# STM32H7P4xx register map
File version: 1.0
Registers are 32-bit, read-write, reset 0x0 unless marked. A register's access mark holds for its fields unless they carry their own. Offsets are from the block's base; [hi:lo] are bit positions; lines under a group give offsets from that group; {n}, {i} and the like mark numbered series; 'fields as' and 'values as' point back to an identical list.

## FLASH — FLASH Registers
Base 0x52002000
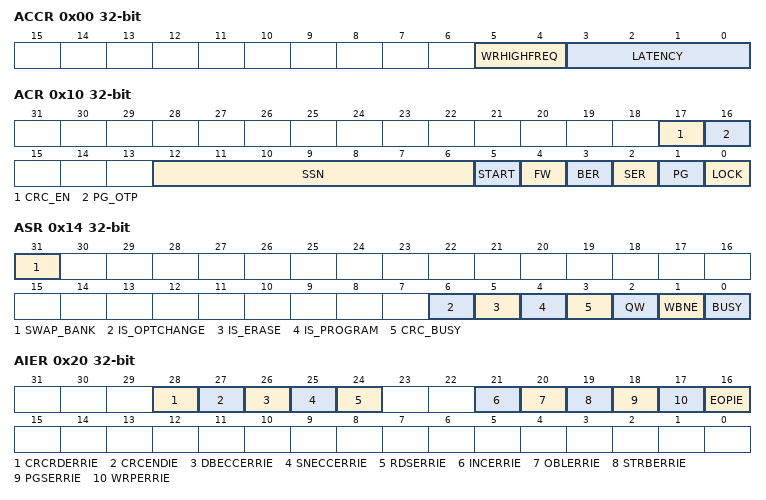
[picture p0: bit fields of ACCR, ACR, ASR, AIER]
0x00 ACCR — FLASH access control register
  [5:4] WRHIGHFREQ — WRHIGHFREQ[1:0] bits (Flash signal delay)
  [3:0] LATENCY — LATENCY[3:0] bits (Read latency)
0x04 AKEYR — FLASH bank A control key register
  [31:0] CUKEY — Control unlock key
0x10 ACR — FLASH bank A control register
  [17] CRC_EN — CRC enable
  [16] PG_OTP — Program Enable for OTP Area
  [12:6] SSN — Sector erase selection number
  [5] START — Erase start control bit
  [4] FW — Force write
  [3] BER — Bank erase request
  [2] SER — Sector erase request
  [1] PG — Internal buffer control bit
  [0] LOCK — Configuration lock bit
0x14 ASR ro — FLASH bank A status register
  [31] SWAP_BANK — SWAP_BANK (Swapped bank)
  [6] IS_OPTCHANGE — Is an option change
  [5] IS_ERASE — Is an erase
  [4] IS_PROGRAM
  [3] CRC_BUSY — CRC busy flag
  [2] QW — Wait queue flag
  [1] WBNE — Write buffer not empty flag
  [0] BUSY — Busy flag
0x20 AIER — FLASH bank A interrupt enable register
  [28] CRCRDERRIE — CRC read error interrupt enable bit
  [27] CRCENDIE — CRC end of calculation interrupt enable bit
  [26] DBECCERRIE — ECC double detection error interrupt enable bit
  [25] SNECCERRIE — ECC single correction error interrupt enable bit
  [24] RDSERRIE — Read security error interrupt enable bit
  [21] INCERRIE — Inconsistency error interrupt enable bit
  [20] OBLERRIE — Option byte loading error interrupt enable bit
  [19] STRBERRIE — Strobe error interrupt enable bit
  [18] PGSERRIE — Programming sequence error interrupt enable bit
  [17] WRPERRIE — Write protection error interrupt enable bit
  [16] EOPIE — End of program interrupt enable bit
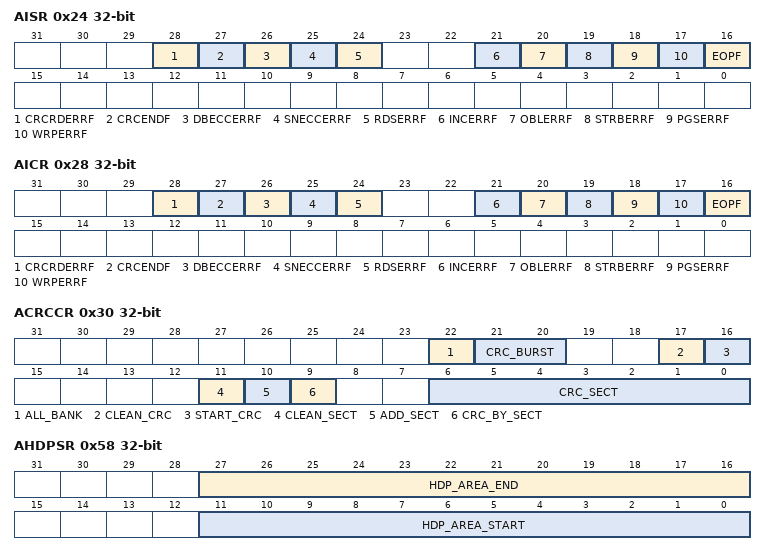
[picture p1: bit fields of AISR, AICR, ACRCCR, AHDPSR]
0x24 AISR ro — FLASH bank A interrupt status register
  [28] CRCRDERRF — CRC read error flag
  [27] CRCENDF — CRC end of calculation flag
  [26] DBECCERRF — ECC double error flag
  [25] SNECCERRF — ECC single error flag
  [24] RDSERRF — Read security error flag
  [21] INCERRF — Inconsistency error flag
  [20] OBLERRF — Option byte loading error flag
  [19] STRBERRF — Strobe error flag
  [18] PGSERRF — Programming sequence error flag
  [17] WRPERRF — Write protection error flag
  [16] EOPF — End of program flag
0x28 AICR — FLASH bank A interrupt clear register
  [28] CRCRDERRF — CRC read error flag clear
  [27] CRCENDF — CRC end flag clear
  [26] DBECCERRF — ECC double error flag clear
  [25] SNECCERRF — ECC single error flag clear
  [24] RDSERRF — Read security error flag clear
  [21] INCERRF — Inconsistency error flag clear
  [20] OBLERRF — Option byte loading error flag clear
  [19] STRBERRF — Strobe error flag clear
  [18] PGSERRF — Programming sequence error flag clear
  [17] WRPERRF — Write protection error flag clear
  [16] EOPF — End of program flag clear
0x30 ACRCCR — FLASH bank A CRC control register
  [22] ALL_BANK — ALL_BANK (All sectors in bank selection)
  [21:20] CRC_BURST — CRC_BURST[1:0] bits (CRC burst size)
  [17] CLEAN_CRC — CLEAN_CRC (CRC clear bit)
  [16] START_CRC — START_CRC (CRC start bit)
  [11] CLEAN_SECT — CLEAN_SECT (CRC sector list clear bit)
  [10] ADD_SECT — ADD_SECT (CRC sector select bit)
  [9] CRC_BY_SECT — CRC_BY_SECT (CRC sector mode select bit)
  [6:0] CRC_SECT — CRC_SECT[6:0] bits (CRC sector number)
0x34 ACRCSADDR — FLASH bank A CRC start address register
  [19:2] CRC_START_ADDR — CRC start address
0x38 ACRCEADDR — FLASH bank A CRC end address register
  [19:2] CRC_END_ADDR — CRC end address
0x3C CRCDATAR ro — FLASH CRC data register
  [31:0] CRC_DATA — CRC result
0x40 AECCSFADDR ro — FLASH bank A ECC single error fail address
  [31:0] SEC_FADD — ECC single error correction fail address
0x44 AECCDFADDR ro — FLASH bank A ECC double error fail address
  [31:0] DED_FADD — ECC double error detection fail address
0x50 AWRPSR ro — FLASH bank A write protection status register
  [31:0] WRPSG — WRPSG[31:0] bits (Write protection for sector group n in bank x (n=0 to 127))
0x54 AWRPSRP — FLASH bank A write protection status register programming
  [31:0] WRPSG — WRPSG[31:0] bits (Write protection for sector group n in bank x programming (n=0 to 127))
0x58 AHDPSR ro — FLASH bank A hide protection status register
  [27:16] HDP_AREA_END — HDP_AREA_END[11:0] bits (Hide protection user flash area end for bank x)
  [11:0] HDP_AREA_START — HDP_AREA_START[11:0] bits (Hide protection user flash area start for bank x)
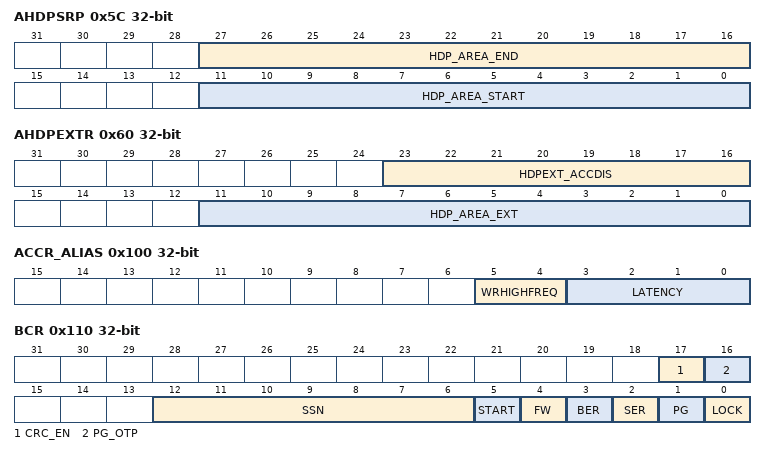
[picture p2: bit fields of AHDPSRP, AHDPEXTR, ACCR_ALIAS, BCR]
0x5C AHDPSRP — FLASH bank A hide protection status register programming
  [27:16] HDP_AREA_END — HDP_AREA_END[11:0] bits (Hide protection user flash area end programming for bank x)
  [11:0] HDP_AREA_START — HDP_AREA_START[11:0] bits (Hide protection user flash area start programming for bank x)
0x60 AHDPEXTR — FLASH bank A HDP extension register
  [23:16] HDPEXT_ACCDIS — HDPEXT_ACCDIS[7:0] bits (HDP extension area access disable for bank x)
  [11:0] HDP_AREA_EXT — HDP_AREA_EXT[11:0] bits (HDP extension area end for bank x)
0x100 ACCR_ALIAS — FLASH access control register
  [5:4] WRHIGHFREQ — Flash signal delay
  [3:0] LATENCY — Read latency
0x104 BKEYR — FLASH bank B control key register
  [31:0] CUKEY — CUKEY[31:0] bits (Control unlock key)
0x110 BCR — FLASH bank B control register
  [17] CRC_EN — CRC_EN (CRC enable)
  [16] PG_OTP — PG_OTP (Program Enable for OTP Area)
  [12:6] SSN — SSN[6:0] bits (Sector erase selection number)
  [5] START — START (Erase start control bit)
  [4] FW — FW (Force write)
  [3] BER — BER (Bank erase request)
  [2] SER — SER (Sector erase request)
  [1] PG — PG (Internal buffer control bit)
  [0] LOCK — LOCK (Configuration lock bit)
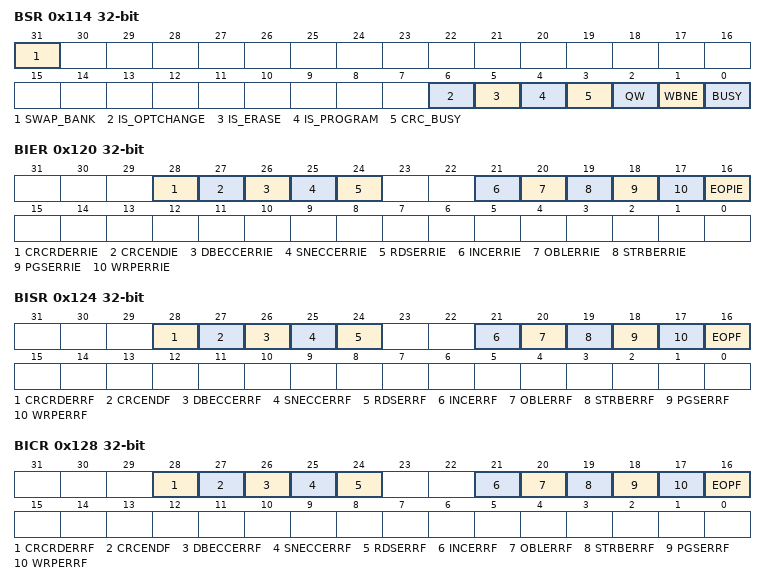
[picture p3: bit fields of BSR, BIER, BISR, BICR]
0x114 BSR ro — FLASH bank B status register
  [31] SWAP_BANK — SWAP_BANK (Swapped bank)
  [6] IS_OPTCHANGE — IS_OPTCHANGE (Is an option change)
  [5] IS_ERASE — IS_ERASE (Is an erase)
  [4] IS_PROGRAM — IS_PROGRAM (Is a program)
  [3] CRC_BUSY — CRC_BUSY (CRC busy flag)
  [2] QW — QW (Wait queue flag)
  [1] WBNE — WBNE (Write buffer not empty flag)
  [0] BUSY — BUSY (Busy flag)
0x120 BIER — FLASH bank B interrupt enable register
  [28] CRCRDERRIE — CRCRDERRIE (CRC read error interrupt enable bit)
  [27] CRCENDIE — CRCENDIE (CRC end of calculation interrupt enable bit)
  [26] DBECCERRIE — DBECCERRIE (ECC double detection error interrupt enable bit)
  [25] SNECCERRIE — SNECCERRIE (ECC single correction error interrupt enable bit)
  [24] RDSERRIE — RDSERRIE (Read security error interrupt enable bit)
  [21] INCERRIE — INCERRIE (Inconsistency error interrupt enable bit)
  [20] OBLERRIE — OBLERRIE (Option byte loading error interrupt enable bit)
  [19] STRBERRIE — STRBERRIE (Strobe error interrupt enable bit)
  [18] PGSERRIE — PGSERRIE (Programming sequence error interrupt enable bit)
  [17] WRPERRIE — WRPERRIE (Write protection error interrupt enable bit)
  [16] EOPIE — EOPIE (End-of-program interrupt control bit)
0x124 BISR ro — FLASH bank B interrupt status register
  [28] CRCRDERRF — CRCRDERRF (CRC read error flag)
  [27] CRCENDF — CRCENDF (CRC end flag)
  [26] DBECCERRF — DBECCERRF (ECC double error flag)
  [25] SNECCERRF — SNECCERRF (ECC single error flag)
  [24] RDSERRF — RDSERRF (Read security error flag)
  [21] INCERRF — INCERRF (Inconsistency error flag)
  [20] OBLERRF — OBLERRF (Option byte loading error flag)
  [19] STRBERRF — STRBERRF (Strobe error flag)
  [18] PGSERRF — PGSERRF (Programming sequence error flag)
  [17] WRPERRF — WRPERRF (Write protection error flag)
  [16] EOPF — EOPF (End-of-program flag)
0x128 BICR — FLASH bank B interrupt clear register
  [28] CRCRDERRF — CRCRDERRF (CRC error flag clear)
  [27] CRCENDF — CRCENDF (CRC end flag clear)
  [26] DBECCERRF — DBECCERRF (ECC double error flag clear)
  [25] SNECCERRF — SNECCERRF (ECC single error flag clear)
  [24] RDSERRF — RDSERRF (Read security error flag clear)
  [21] INCERRF — INCERRF (Inconsistency error flag clear)
  [20] OBLERRF — OBLERRF (Option byte loading error flag clear)
  [19] STRBERRF — STRBERRF (Strobe error flag clear)
  [18] PGSERRF — PGSERRF (Programming sequence error flag clear)
  [17] WRPERRF — WRPERRF (Write protection error flag clear)
  [16] EOPF — EOPF (End-of-program flag clear)
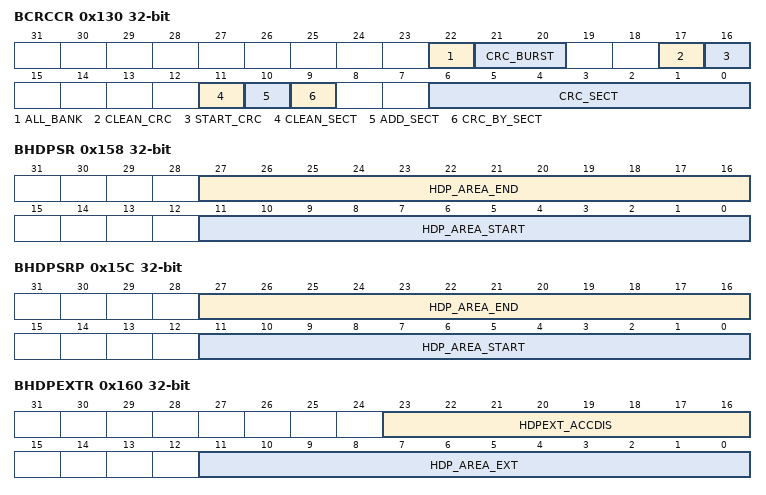
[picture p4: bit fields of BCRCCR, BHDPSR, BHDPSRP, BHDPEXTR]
0x130 BCRCCR — FLASH bank B CRC control register
  fields as ACRCCR
0x134 BCRCSADDR — FLASH bank B CRC start address register
  [19:2] CRC_START_ADDR — CRC_START_ADDR[17:0] bits (CRC start address)
0x138 BCRCEADDR — FLASH bank B CRC end address register
  [19:2] CRC_END_ADDR — CRC_END_ADDR[17:0] bits (CRC end address)
0x13C CRCDATAR_ALIAS ro — FLASH CRC data register
  [31:0] CRC_DATA — CRC result
0x140 BECCSFADDR ro — FLASH bank B ECC single error fail address
  [31:0] SEC_FADD — SEC_FADD[31:0] bits (ECC single error correction fail address)
0x144 BECCDFADDR ro — FLASH bank B ECC double error fail address
  [31:0] DED_FADD — DED_FADD[31:0] bits (ECC double error detection fail address)
0x150 BWRPSR ro — FLASH bank B write protection status register
  fields as AWRPSR
0x154 BWRPSRP — FLASH bank B write protection status register programming
  fields as AWRPSRP
0x158 BHDPSR ro — FLASH bank B hide protection status register
  fields as AHDPSR
0x15C BHDPSRP — FLASH bank B hide protection status register programming
  fields as AHDPSRP
0x160 BHDPEXTR — FLASH bank B HDP extension register
  fields as AHDPEXTR
0x200 OPTKEYR — FLASH options key register
  [31:0] OCUKEY — OCUKEY[31:0] bits (Options configuration unlock key)
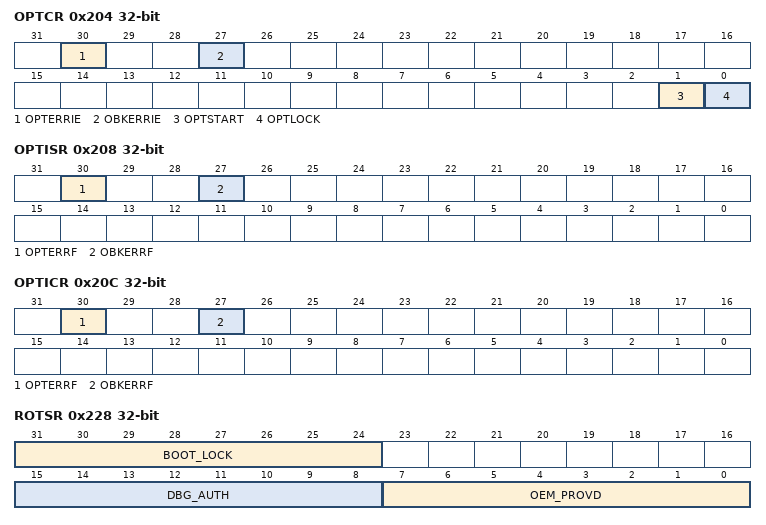
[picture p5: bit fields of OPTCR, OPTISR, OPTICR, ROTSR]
0x204 OPTCR — FLASH options control register
  [30] OPTERRIE — OPTERRIE (Option byte change error interrupt enable bit)
  [27] OBKERRIE — OBKERRIE (Option byte key error interrupt enable bit)
  [1] OPTSTART — OPTSTART (Options update start)
  [0] OPTLOCK — OPTLOCK (Options lock)
0x208 OPTISR ro — FLASH options interrupt status register
  [30] OPTERRF — OPTERRF (Option byte change error flag)
  [27] OBKERRF — OBKERRF (Option byte key error flag)
0x20C OPTICR — FLASH options interrupt clear register
  fields as OPTISR
0x210 OTPLSR ro — FLASH OTP lock status register
  [15:0] OTPL — OTPL[15:0] bits (OTP lock n (n=0 to 15))
0x214 OTPLSRP — FLASH OTP lock status register programming
  [15:0] OTPL — OTPL[15:0] bits (OTP lock n programming (n=0 to 15))
0x220 NVSR ro — FLASH non-volatile status register
  [7:0] NVSTATE — NVSTATE[7:0] bits (Non-volatile state)
0x224 NVSRP — FLASH security status register programming
  [7:0] NVSTATE — NVSTATE[7:0] bits (Non-volatile state programming)
0x228 ROTSR ro — FLASH RoT status register
  [31:24] BOOT_LOCK — BOOT_LOCK[7:0] bits (boot lock)
  [15:8] DBG_AUTH — DBG_AUTH[7:0] bits (Debug authentication method)
  [7:0] OEM_PROVD — OEM_PROVD[7:0] bits (OEM provisioned device)
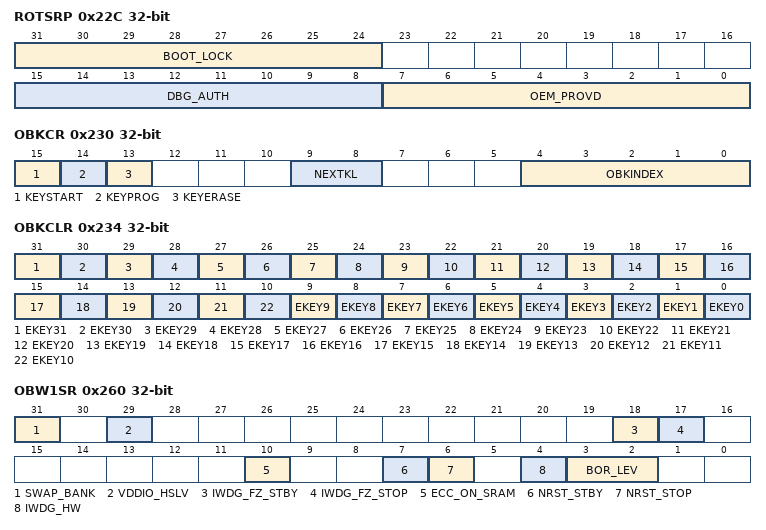
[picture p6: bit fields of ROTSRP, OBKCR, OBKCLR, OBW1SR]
0x22C ROTSRP — FLASH RoT status register programming
  [31:24] BOOT_LOCK — BOOT_LOCK[7:0] bits (Boot lock programming)
  [15:8] DBG_AUTH — DBG_AUTH[7:0] bits (Debug authentication method programming)
  [7:0] OEM_PROVD — OEM_PROVD[7:0] bits (OEM provisioned device)
0x230 OBKCR — FLASH option byte key control register
  [15] KEYSTART — KEYSTART (Key option start)
  [14] KEYPROG — KEYPROG (Key program)
  [13] KEYERASE — KEYERASE (Key erase)
  [9:8] NEXTKL — NEXTKL[1:0] bits (Next key level)
  [4:0] OBKINDEX — OBKINDEX[4:0] bits (Option byte key index)
0x234 OBKCLR — FLASH option byte key clear register
  [31] EKEY31 — EKEY31 (Erase key {i})
  [30] EKEY30 — EKEY30 (Erase key {i})
  [29] EKEY29 — EKEY29 (Erase key {i})
  [28] EKEY28 — EKEY28 (Erase key {i})
  [27] EKEY27 — EKEY27 (Erase key {i})
  [26] EKEY26 — EKEY26 (Erase key {i})
  [25] EKEY25 — EKEY25 (Erase key {i})
  [24] EKEY24 — EKEY24 (Erase key {i})
  [23] EKEY23 — EKEY23 (Erase key {i})
  [22] EKEY22 — EKEY22 (Erase key {i})
  [21] EKEY21 — EKEY21 (Erase key {i})
  [20] EKEY20 — EKEY20 (Erase key {i})
  [19] EKEY19 — EKEY19 (Erase key {i})
  [18] EKEY18 — EKEY18 (Erase key {i})
  [17] EKEY17 — EKEY17 (Erase key {i})
  [16] EKEY16 — EKEY16 (Erase key {i})
  [15] EKEY15 — EKEY15 (Erase key {i})
  [14] EKEY14 — EKEY14 (Erase key {i})
  [13] EKEY13 — EKEY13 (Erase key {i})
  [12] EKEY12 — EKEY12 (Erase key {i})
  [11] EKEY11 — EKEY11 (Erase key {i})
  [10] EKEY10 — EKEY10 (Erase key {i})
  [9] EKEY9 — EKEY9 (Erase key {i})
  [8] EKEY8 — EKEY8 (Erase key {i})
  [7] EKEY7 — EKEY7 (Erase key {i})
  [6] EKEY6 — EKEY6 (Erase key {i})
  [5] EKEY5 — EKEY5 (Erase key {i})
  [4] EKEY4 — EKEY4 (Erase key {i})
  [3] EKEY3 — EKEY3 (Erase key {i})
  [2] EKEY2 — EKEY2 (Erase key {i})
  [1] EKEY1 — EKEY1 (Erase key {i})
  [0] EKEY0 — EKEY0 (Erase key {i})
{0x240+4i} OBKDR{i} (i=0..3) — FLASH option bytes key data register {i}
  [31:0] OBKDATA — OBKDATA[31:0] bits (option byte key data, bits [31+x:0+x])
0x260 OBW1SR ro — FLASH option byte word 1 status register
  [31] SWAP_BANK — SWAP_BANK (Bank Swapping)
  [29] VDDIO_HSLV — VDDIO_HSLV (I/O High-Speed at Low-Voltage)
  [18] IWDG_FZ_STBY — IWDG standby mode freeze
  [17] IWDG_FZ_STOP — IWDG_FZ_STOP (IWDG stop mode freeze)
  [10] ECC_ON_SRAM — ECC_ON_SRAM (ECC on SRAM)
  [7] NRST_STBY — NRST_STBY (Reset on standby mode)
  [6] NRST_STOP — NRST_STOP (Reset on stop mode)
  [4] IWDG_HW — IWDG_HW (Independent watchdog HW Control)
  [3:2] BOR_LEV — BOR_LEV[1:0] bits (Brownout level)
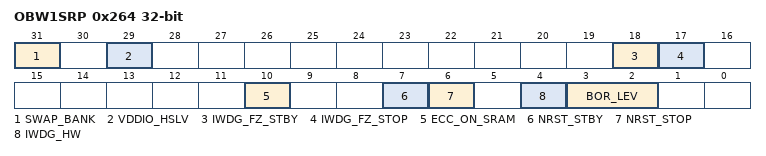
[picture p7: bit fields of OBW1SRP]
0x264 OBW1SRP — FLASH option byte word 1 status register programming
  [31] SWAP_BANK — SWAP_BANK (Bank Swapping programming)
  [29] VDDIO_HSLV — VDDIO_HSLV (I/O High-Speed at Low-Voltage programming)
  [18] IWDG_FZ_STBY — IWDG standby mode freeze programming
  [17] IWDG_FZ_STOP — IWDG_FZ_STOP (IWDG stop mode freeze)
  [10] ECC_ON_SRAM — ECC_ON_SRAM (ECC on SRAM)
  [7] NRST_STBY — NRST_STBY (Reset on standby mode programming)
  [6] NRST_STOP — NRST_STOP (Reset on stop mode programming)
  [4] IWDG_HW — IWDG_HW (Independent watchdog HW Control)
  [3:2] BOR_LEV — BOR_LEV[1:0] bits (Brownout level)
